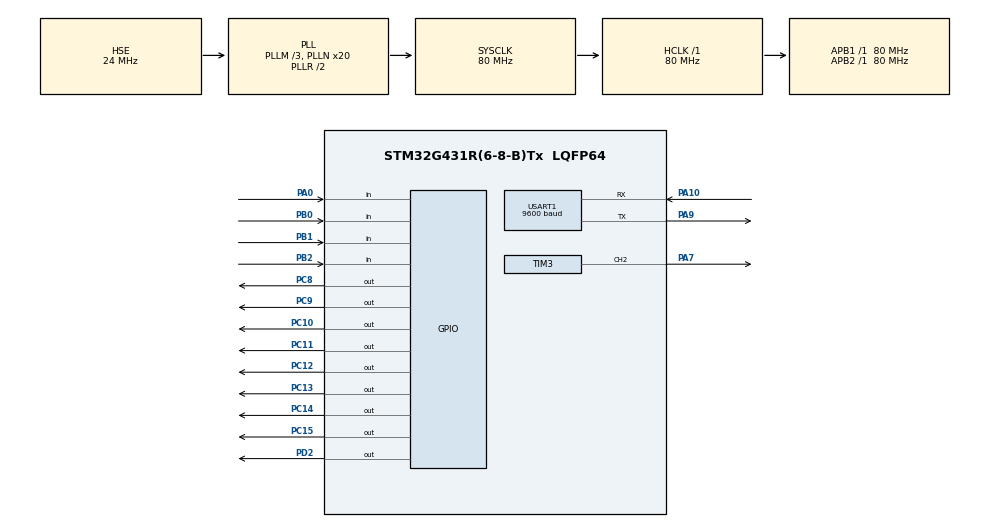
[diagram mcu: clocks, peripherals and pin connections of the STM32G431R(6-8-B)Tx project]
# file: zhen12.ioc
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Mcu.Family=STM32G4
Mcu.Name=STM32G431R(6-8-B)Tx
Mcu.Package=LQFP64
NVIC.PriorityGroup=NVIC_PRIORITYGROUP_4
NVIC.USART1_IRQn=true\:0\:0\:false\:false\:true\:true\:true\:true
PA0.GPIO_PuPd=GPIO_PULLUP
PA0.Signal=GPIO_Input
PA10.Mode=Asynchronous
PA10.Signal=USART1_RX
PA13.Mode=Serial_Wire
PA13.Signal=SYS_JTMS-SWDIO
PA14.Mode=Serial_Wire
PA14.Signal=SYS_JTCK-SWCLK
PA7.Signal=S_TIM3_CH2
PA9.Mode=Asynchronous
PA9.Signal=USART1_TX
PB0.GPIO_PuPd=GPIO_PULLUP
PB0.Signal=GPIO_Input
PB1.GPIO_PuPd=GPIO_PULLUP
PB1.Signal=GPIO_Input
PB2.GPIO_PuPd=GPIO_PULLUP
PB2.Signal=GPIO_Input
PC10.PinState=GPIO_PIN_SET
PC10.Signal=GPIO_Output
PC11.PinState=GPIO_PIN_SET
PC11.Signal=GPIO_Output
PC12.PinState=GPIO_PIN_SET
PC12.Signal=GPIO_Output
PC13.PinState=GPIO_PIN_SET
PC13.Signal=GPIO_Output
PC14-OSC32_IN.PinState=GPIO_PIN_SET
PC14-OSC32_IN.Signal=GPIO_Output
PC15-OSC32_OUT.PinState=GPIO_PIN_SET
PC15-OSC32_OUT.Signal=GPIO_Output
PC8.PinState=GPIO_PIN_SET
PC8.Signal=GPIO_Output
PC9.PinState=GPIO_PIN_SET
PC9.Signal=GPIO_Output
PD2.PinState=GPIO_PIN_SET
PD2.Signal=GPIO_Output
PF0-OSC_IN.Mode=HSE-External-Oscillator
PF0-OSC_IN.Signal=RCC_OSC_IN
PF1-OSC_OUT.Mode=HSE-External-Oscillator
PF1-OSC_OUT.Signal=RCC_OSC_OUT
ProjectManager.HeapSize=0x200
ProjectManager.StackSize=0x400
ProjectManager.TargetToolchain=MDK-ARM V5.32
RCC.ADC12Freq_Value=80000000
RCC.AHBFreq_Value=80000000
RCC.APB1Freq_Value=80000000
RCC.APB1TimFreq_Value=80000000
RCC.APB2Freq_Value=80000000
RCC.APB2TimFreq_Value=80000000
RCC.CortexFreq_Value=80000000
RCC.EXTERNAL_CLOCK_VALUE=12288000
RCC.HCLKFreq_Value=80000000
RCC.HSE_VALUE=24000000
RCC.HSI48_VALUE=48000000
RCC.HSI_VALUE=16000000
RCC.LSE_VALUE=32768
RCC.PLLM=RCC_PLLM_DIV3
RCC.PLLN=20
RCC.PLLSourceVirtual=RCC_PLLSOURCE_HSE
RCC.SYSCLKFreq_VALUE=80000000
RCC.SYSCLKSource=RCC_SYSCLKSOURCE_PLLCLK
RCC.USBFreq_Value=80000000
RCC.VCOOutputFreq_Value=160000000
SH.S_TIM3_CH2.0=TIM3_CH2,PWM Generation2 CH2
TIM2.Prescaler=8000-1
TIM3.Channel-PWM\ Generation2\ CH2=TIM_CHANNEL_2
TIM3.PeriodNoDither=100-1
TIM3.Prescaler=400-1
TIM4.Prescaler=8000-1
USART1.BaudRate=9600
USART1.VirtualMode-Asynchronous=VM_ASYNC
VP_SYS_VS_DBSignals.Mode=DisableDeadBatterySignals
VP_TIM2_VS_ClockSourceINT.Mode=Internal
VP_TIM4_VS_ClockSourceINT.Mode=Internal
board=custom

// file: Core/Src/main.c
/* USER CODE BEGIN Header */
/**
  ******************************************************************************
  * @file           : main.c
  * @brief          : Main program body
  ******************************************************************************
  * @attention
  *
  * Copyright (c) 2025 STMicroelectronics.
  * All rights reserved.
  *
  * This software is licensed under terms that can be found in the LICENSE file
  * in the root directory of this software component.
  * If no LICENSE file comes with this software, it is provided AS-IS.
  *
  ******************************************************************************
  */
/* USER CODE END Header */
#include "main.h"
#include "tim.h"
#include "usart.h"
#include "gpio.h"

/* USER CODE BEGIN Includes */
#include "headfile.h"
/* USER CODE END Includes */

void SystemClock_Config(void);

int main(void)
{

  /* MCU Configuration--------------------------------------------------------*/

  /* Reset of all peripherals, Initializes the Flash interface and the Systick. */
  HAL_Init();

  /* Configure the system clock */
  SystemClock_Config();

  /* Initialize all configured peripherals */
  MX_GPIO_Init();
  MX_TIM3_Init();
  MX_TIM4_Init();
  MX_USART1_UART_Init();
  MX_TIM2_Init();
  /* USER CODE BEGIN 2 */
  	HAL_GPIO_WritePin(GPIOD,GPIO_PIN_2, GPIO_PIN_RESET);

	LCD_Init();
	LCD_Clear(Black);
	LCD_SetBackColor(Black);
	LCD_SetTextColor(White);

	HAL_TIM_PWM_Start(&htim3,TIM_CHANNEL_2);

	HAL_UART_Receive_IT(&huart1,&buff,1);

	HAL_TIM_Base_Start(&htim2);
  /* USER CODE END 2 */

  /* Infinite loop */
  /* USER CODE BEGIN WHILE */
  while (1)
  {

	lcd_show();
	key_scan();
	usart_process();

    /* USER CODE END WHILE */

  }
}

void SystemClock_Config(void)
{
  RCC_OscInitTypeDef RCC_OscInitStruct = {0};
  RCC_ClkInitTypeDef RCC_ClkInitStruct = {0};

  /** Configure the main internal regulator output voltage
  */
  HAL_PWREx_ControlVoltageScaling(PWR_REGULATOR_VOLTAGE_SCALE1);

  /** Initializes the RCC Oscillators according to the specified parameters
  * in the RCC_OscInitTypeDef structure.
  */
  RCC_OscInitStruct.OscillatorType = RCC_OSCILLATORTYPE_HSE;
  RCC_OscInitStruct.HSEState = RCC_HSE_ON;
  RCC_OscInitStruct.PLL.PLLState = RCC_PLL_ON;
  RCC_OscInitStruct.PLL.PLLSource = RCC_PLLSOURCE_HSE;
  RCC_OscInitStruct.PLL.PLLM = RCC_PLLM_DIV3;
  RCC_OscInitStruct.PLL.PLLN = 20;
  RCC_OscInitStruct.PLL.PLLP = RCC_PLLP_DIV2;
  RCC_OscInitStruct.PLL.PLLQ = RCC_PLLQ_DIV2;
  RCC_OscInitStruct.PLL.PLLR = RCC_PLLR_DIV2;
  if (HAL_RCC_OscConfig(&RCC_OscInitStruct) != HAL_OK)
  {
    Error_Handler();
  }

  /** Initializes the CPU, AHB and APB buses clocks
  */
  RCC_ClkInitStruct.ClockType = RCC_CLOCKTYPE_HCLK|RCC_CLOCKTYPE_SYSCLK
                              |RCC_CLOCKTYPE_PCLK1|RCC_CLOCKTYPE_PCLK2;
  RCC_ClkInitStruct.SYSCLKSource = RCC_SYSCLKSOURCE_PLLCLK;
  RCC_ClkInitStruct.AHBCLKDivider = RCC_SYSCLK_DIV1;
  RCC_ClkInitStruct.APB1CLKDivider = RCC_HCLK_DIV1;
  RCC_ClkInitStruct.APB2CLKDivider = RCC_HCLK_DIV1;

  if (HAL_RCC_ClockConfig(&RCC_ClkInitStruct, FLASH_LATENCY_2) != HAL_OK)
  {
    Error_Handler();
  }
}

void Error_Handler(void)
{
  __disable_irq();
  while (1)
  {
  }
}
